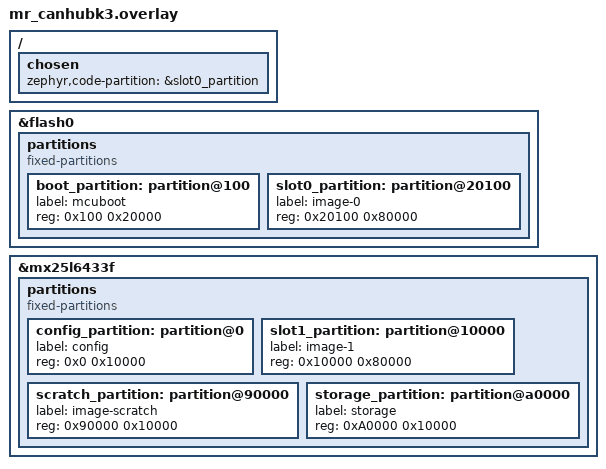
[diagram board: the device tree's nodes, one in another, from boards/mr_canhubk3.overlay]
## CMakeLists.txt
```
cmake_minimum_required(VERSION 3.20.0)

find_package(Zephyr REQUIRED HINTS $ENV{ZEPHYR_BASE})
project(ceell VERSION 0.1.0)

add_subdirectory(ceell)

target_sources(app PRIVATE src/main.c)
```

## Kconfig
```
mainmenu "CEELL Middleware Configuration"

rsource "Kconfig.ceell"

source "Kconfig.zephyr"
```

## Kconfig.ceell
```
menu "CEELL Services"

config CEELL_MAX_SERVICES
	int "Maximum number of services per node"
	default 4

config CEELL_MSG_PORT
	int "UDP port for service messaging"
	default 5556

config CEELL_PEER_TIMEOUT_MS
	int "Peer expiry timeout in milliseconds"
	default 5000

config CEELL_TEST_ECHO_SERVICE
	bool "Enable built-in echo test service"
	default n

endmenu

menu "CEELL Discovery"

config CEELL_DISCOVERY_PORT
	int "UDP port for discovery"
	default 5555

config CEELL_DISCOVERY_GROUP
	string "Multicast group address"
	default "224.0.1.100"

config CEELL_DISCOVERY_INTERVAL_MS
	int "Announcement interval in milliseconds"
	default 1000

config CEELL_DISCOVERY_MAX_PEERS
	int "Maximum number of tracked peers"
	default 8

endmenu

menu "CEELL Node Identity"

config CEELL_NODE_ID_DEFAULT
	int "Default node ID (used if flash config is empty)"
	default 0

config CEELL_NODE_ROLE_DEFAULT
	string "Default node role"
	default "unknown"

config CEELL_NODE_NAME_DEFAULT
	string "Default node name"
	default "ceell-unprovisioned"

config CEELL_NODE_IP_DEFAULT
	string "Default IP address"
	default "192.168.1.100"

config CEELL_NODE_NETMASK_DEFAULT
	string "Default netmask"
	default "255.255.255.0"

endmenu

menu "CEELL OTA Firmware Updates"

config CEELL_OTA
	bool "Enable OTA firmware update client"
	default n
	depends on BOOTLOADER_MCUBOOT
	depends on NET_TCP
	depends on HTTP_CLIENT
	depends on IMG_MANAGER
	depends on STREAM_FLASH
	help
	  Enable over-the-air firmware update support. The OTA client
	  periodically polls an HTTP server for a firmware manifest,
	  downloads new images to the secondary slot, and triggers
	  MCUboot to swap on reboot.

config CEELL_OTA_SERVER_HOST
	string "OTA server IP address"
	default "192.168.1.1"
	depends on CEELL_OTA

config CEELL_OTA_SERVER_PORT
	int "OTA server HTTP port"
	default 8080
	depends on CEELL_OTA

config CEELL_OTA_CHECK_INTERVAL_SEC
	int "Seconds between automatic update checks"
	default 300
	depends on CEELL_OTA

config CEELL_OTA_MANIFEST_PATH
	string "HTTP path to firmware manifest JSON"
	default "/firmware/latest.json"
	depends on CEELL_OTA

config CEELL_OTA_AUTO_CONFIRM
	bool "Automatically confirm image on successful boot"
	default y
	depends on CEELL_OTA
	help
	  When enabled, the running firmware is automatically confirmed
	  after a successful boot. If disabled, the application must
	  call boot_write_img_confirmed() explicitly — otherwise MCUboot
	  will revert to the previous image on the next reboot.

config CEELL_OTA_USE_TLS
	bool "Use HTTPS for OTA downloads"
	default n
	depends on CEELL_OTA
	depends on TLS_CREDENTIALS
	help
	  Enable TLS for OTA downloads. Requires additional heap (~49KB)
	  and a TLS credential configured for the server certificate.

endmenu

menu "CEELL Safety Messaging"

config CEELL_MSG_DISPATCHER_PRIORITY
	int "Dispatcher thread priority"
	default 5
	help
	  Priority of the message dispatcher thread. This thread reads
	  incoming UDP packets and routes them to per-priority queues.
	  Should be higher priority (lower number) than normal handlers.

config CEELL_MSG_CRITICAL_PRIORITY
	int "Critical message handler thread priority"
	default 2
	help
	  Priority of the thread that processes CRITICAL (safety) messages.
	  This is the highest priority handler — used for brake, steer, and
	  other safety-critical commands. Must be lower (higher priority)
	  than all other handler threads.

config CEELL_MSG_NORMAL_PRIORITY
	int "Normal message handler thread priority"
	default 7
	help
	  Priority of the thread that processes NORMAL (standard) messages.
	  Used for regular service requests and responses.

config CEELL_MSG_BULK_PRIORITY
	int "Bulk message handler thread priority"
	default 10
	help
	  Priority of the thread that processes BULK (low priority) messages.
	  Used for diagnostics, OTA status, and telemetry. Runs at the
	  lowest priority of all handler threads.

config CEELL_MSG_QUEUE_DEPTH
	int "Per-priority message queue depth"
	default 8
	help
	  Maximum number of messages that can be queued for each priority
	  level (CRITICAL, NORMAL, BULK). If a queue is full, incoming
	  messages of that priority are dropped with an error response.

endmenu

menu "CEELL Timing & Determinism"

config CEELL_TIMING
	bool "Enable timing measurement framework"
	default y
	help
	  Enable the timing measurement subsystem. Provides a ring buffer
	  of timing samples with per-label statistics (min/max/avg).
	  Uses the hardware cycle counter for sub-microsecond precision.

config CEELL_TIMING_SAMPLES
	int "Number of timing sample slots in ring buffer"
	default 64
	depends on CEELL_TIMING
	help
	  Size of the ring buffer that stores timing measurements.
	  Older samples are overwritten when the buffer is full.

config CEELL_TIMING_BUDGETS
	bool "Enable timing budget checks"
	default y
	depends on CEELL_TIMING
	help
	  Enable timing budgets for critical code paths. Each budget
	  defines a maximum acceptable duration; violations are counted
	  and repeated consecutive violations (3+) trigger a warning
	  that would escalate to safe state in production.

config CEELL_TSN
	bool "Enable TSN traffic class mapping"
	default n
	help
	  Enable IEEE 802.1Q TSN (Time-Sensitive Networking) traffic class
	  mapping. Maps CEELL message priorities to 802.1Q PCP values.
	  Currently stubbed — requires TSN-capable hardware (e.g. S32K5xx
	  ENETC) for actual queue scheduling.

endmenu

menu "CEELL Redundancy & Fault Tolerance"

config CEELL_MSG_REDUNDANT
	bool "Enable dual-path redundant messaging"
	default n
	help
	  Enable a secondary UDP socket for redundant message delivery.
	  Messages are sent on both the primary and secondary paths.
	  A deduplication ring buffer discards duplicate sequence numbers
	  received on either path.

config CEELL_MSG_PORT_SECONDARY
	int "Secondary UDP port for redundant messaging"
	default 5557
	depends on CEELL_MSG_REDUNDANT
	help
	  UDP port number for the secondary redundant messaging path.

config CEELL_SAFE_STATE
	bool "Enable safe state management"
	default y
	help
	  Enable the safe state manager. Provides an atomic safe-state
	  flag with callback notification. Modules can trigger safe state
	  when critical faults are detected (peer loss, deadline exceeded,
	  communication failure).

config CEELL_WATCHDOG
	bool "Enable software watchdog"
	default n
	depends on CEELL_SAFE_STATE
	help
	  Enable a software watchdog timer. If ceell_watchdog_feed() is not
	  called within the configured timeout, the watchdog triggers safe
	  state via ceell_safe_state_trigger(). The lifecycle loop should
	  call ceell_watchdog_feed() each tick.

config CEELL_WATCHDOG_TIMEOUT_MS
	int "Software watchdog timeout in milliseconds"
	default 10000
	depends on CEELL_WATCHDOG
	help
	  Maximum time between watchdog feeds before safe state is triggered.
	  Should be set to a value larger than the lifecycle tick interval.

endmenu
```

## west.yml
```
manifest:
  remotes:
    - name: zephyrproject-rtos
      url-base: https://github.com/zephyrproject-rtos

  projects:
    - name: zephyr
      remote: zephyrproject-rtos
      revision: v4.1.0
      import:
        name-allowlist:
          - cmsis
          - hal_nxp
          - picolibc
          - mbedtls
          - zcbor
    - name: mcuboot
      remote: zephyrproject-rtos
      revision: 346f7374ff4467e40b5594658f8ac67a5e9813c9
      path: bootloader/mcuboot

  self:
    path: ceell-app
```

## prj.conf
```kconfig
# CEELL Middleware - Base Configuration

# Networking
CONFIG_NETWORKING=y
CONFIG_NET_IPV4=y
CONFIG_NET_UDP=y
CONFIG_NET_SOCKETS=y
CONFIG_NET_IPV4_IGMP=y
CONFIG_NET_L2_ETHERNET=y
CONFIG_NET_DHCPV4=n

# IP set programmatically by ceell_net_setup() — no compile-time address
CONFIG_NET_CONFIG_SETTINGS=n

# Network buffers
CONFIG_NET_PKT_RX_COUNT=16
CONFIG_NET_PKT_TX_COUNT=16
CONFIG_NET_BUF_RX_COUNT=32
CONFIG_NET_BUF_TX_COUNT=32
CONFIG_NET_MAX_CONTEXTS=6

# JSON
CONFIG_JSON_LIBRARY=y

# Flash
CONFIG_FLASH=y
CONFIG_FLASH_MAP=y

# Threading
CONFIG_MAIN_STACK_SIZE=2048
CONFIG_SYSTEM_WORKQUEUE_STACK_SIZE=2048

# Logging
CONFIG_PRINTK=y

# Random (needed by networking stack)
CONFIG_TEST_RANDOM_GENERATOR=y

# No dynamic allocation
CONFIG_HEAP_MEM_POOL_SIZE=0

# CEELL app defaults (un-provisioned identity)
CONFIG_CEELL_DISCOVERY_PORT=5555
CONFIG_CEELL_DISCOVERY_GROUP="224.0.1.100"
CONFIG_CEELL_DISCOVERY_INTERVAL_MS=1000
CONFIG_CEELL_DISCOVERY_MAX_PEERS=8
CONFIG_CEELL_NODE_ID_DEFAULT=0
CONFIG_CEELL_NODE_ROLE_DEFAULT="unknown"
CONFIG_CEELL_NODE_NAME_DEFAULT="ceell-unprovisioned"
CONFIG_CEELL_NODE_IP_DEFAULT="192.168.1.100"
CONFIG_CEELL_NODE_NETMASK_DEFAULT="255.255.255.0"
CONFIG_CEELL_MAX_SERVICES=4
CONFIG_CEELL_MSG_PORT=5556
CONFIG_CEELL_PEER_TIMEOUT_MS=5000
CONFIG_CEELL_TEST_ECHO_SERVICE=y
```

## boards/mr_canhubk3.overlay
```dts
/* CEELL device tree overlay for MR-CANHUBK3
 * Flash layout for MCUboot + OTA firmware updates
 *
 * Internal flash (flash0, ~4MB @ 0x400000):
 *   0x000    -  0x0FF     ivt_header      (256B, from base DTS)
 *   0x100    -  0x200FF   boot_partition  (128KB, MCUboot)
 *   0x20100  -  0xA00FF   slot0_partition (512KB, primary app)
 *
 * External QSPI (mx25l6433f, 8MB):
 *   0x00000  - 0x0FFFF    config_partition  (64KB, node JSON config)
 *   0x10000  - 0x8FFFF    slot1_partition   (512KB, OTA download target)
 *   0x90000  - 0x9FFFF    scratch_partition (64KB, MCUboot swap scratch)
 *   0xA0000  - 0xAFFFF    storage_partition (64KB, general storage)
 */

/* --- Internal flash: add MCUboot + slot0, replace code_partition --- */
&flash0 {
	partitions {
		compatible = "fixed-partitions";
		#address-cells = <1>;
		#size-cells = <1>;

		/* Delete the default code_partition from base DTS */
		/delete-node/ partition@100;

		boot_partition: partition@100 {
			label = "mcuboot";
			reg = <0x100 0x20000>;
		};

		slot0_partition: partition@20100 {
			label = "image-0";
			reg = <0x20100 0x80000>;
		};
	};
};

/* --- External QSPI: config + slot1 + scratch + storage --- */
&mx25l6433f {
	partitions {
		compatible = "fixed-partitions";
		#address-cells = <1>;
		#size-cells = <1>;

		/delete-node/ partition@0;

		config_partition: partition@0 {
			label = "config";
			reg = <0x0 0x10000>;
		};

		slot1_partition: partition@10000 {
			label = "image-1";
			reg = <0x10000 0x80000>;
		};

		scratch_partition: partition@90000 {
			label = "image-scratch";
			reg = <0x90000 0x10000>;
		};

		storage_partition: partition@a0000 {
			label = "storage";
			reg = <0xA0000 0x10000>;
		};
	};
};

/* Point code-partition to slot0 for MCUboot chain boot */
/ {
	chosen {
		zephyr,code-partition = &slot0_partition;
	};
};
```

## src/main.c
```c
/* REQ-SAF-001 */

#include <string.h>

#include "osal_log.h"
#include "config_parser.h"
#include "net_setup.h"
#include "node_identity.h"
#include "service_registry.h"
#include "discovery.h"
#include "messaging.h"
#include "lifecycle.h"
#include "health_monitor.h"
#include "safe_state.h"
#include "timing.h"

#ifdef CONFIG_CEELL_OTA
#include "ota_client.h"
#endif

#ifdef CONFIG_CEELL_TEST_ECHO_SERVICE
static int echo_handler(const char *payload, char *rsp_payload, size_t rsp_len)
{
	strncpy(rsp_payload, payload, rsp_len - 1);
	rsp_payload[rsp_len - 1] = '\0';
	return 0;
}
#endif

static void on_health_change(uint32_t node_id, int old_state, int new_state)
{
	ceell_printk("CEELL: Peer %u health: %d -> %d\n",
		     node_id, old_state, new_state);

	if (new_state == CEELL_HEALTH_LOST) {
		ceell_safe_state_trigger(CEELL_SAFE_CRITICAL_PEER_LOST);
		ceell_printk("CEELL: SAFE STATE TRIGGERED peer=%u\n", node_id);
	} else if (old_state == CEELL_HEALTH_LOST &&
		   new_state == CEELL_HEALTH_HEALTHY) {
		ceell_safe_state_clear();
		ceell_printk("CEELL: SAFE STATE CLEARED peer=%u\n", node_id);
	}
}

int main(void)
{
	struct ceell_config cfg;
	int ret;

	ceell_printk("CEELL middleware starting\n");

	/* Step 1: Load config from flash (or defaults) */
	ret = ceell_config_load(&cfg);
	if (ret < 0) {
		ceell_printk("CEELL: fatal config error (%d)\n", ret);
		return ret;
	}
	ceell_printk("CEELL: Config loaded (from_flash=%d version=%u)\n",
		     cfg.from_flash, cfg.version);

	/* Step 2: Set IP + netmask on Ethernet interface */
	ret = ceell_net_setup(&cfg);
	if (ret < 0) {
		ceell_printk("CEELL: net setup failed (%d)\n", ret);
		return ret;
	}

	/* Step 3: Set node identity */
	ret = ceell_identity_init(&cfg);
	if (ret < 0 && ret != -EALREADY) {
		ceell_printk("CEELL: identity init failed (%d)\n", ret);
		return ret;
	}

	/* Step 4: Initialize service registry */
	ceell_service_init();

	/* Step 5: Register services from config with SLA data */
	for (int i = 0; i < cfg.service_count; i++) {
		if (cfg.version == CEELL_CONFIG_VERSION_V2) {
			/* V2: register with per-service SLA */
			ret = ceell_service_register_sla(
				cfg.services[i], NULL,
				cfg.service_slas[i].priority,
				cfg.service_slas[i].deadline_ms);
		} else {
			/* V1 or defaults: register with default SLA */
			ret = ceell_service_register(cfg.services[i], NULL);
		}
		if (ret < 0) {
			ceell_printk("CEELL: failed to register service "
				     "'%s' (%d)\n", cfg.services[i], ret);
		}
	}

#ifdef CONFIG_CEELL_TEST_ECHO_SERVICE
	ceell_service_register("echo", echo_handler);
#endif

	/* Step 5b: Initialize timing subsystem */
	ceell_timing_init();
	ceell_printk("CEELL: Timing subsystem initialized\n");

	/* Step 5c: Initialize health monitor */
	ret = ceell_health_init();
	if (ret < 0) {
		ceell_printk("CEELL: health init failed (%d)\n", ret);
	} else {
		ceell_health_register_cb(on_health_change);
		ceell_printk("CEELL: Health monitor initialized\n");
	}

	/* Step 5d: Initialize safe state manager */
	ret = ceell_safe_state_init();
	if (ret < 0) {
		ceell_printk("CEELL: safe state init failed (%d)\n", ret);
	} else {
		ceell_printk("CEELL: Safe state manager initialized\n");
	}

	/* Step 6: Initialize discovery */
	ret = ceell_discovery_init();
	if (ret < 0) {
		ceell_printk("CEELL: discovery init failed (%d)\n", ret);
		return ret;
	}

	/* Step 7: Start discovery threads */
	ceell_discovery_start();
	ceell_printk("CEELL: Discovery started\n");

	/* Step 8: Initialize messaging */
	ret = ceell_messaging_init();
	if (ret < 0) {
		ceell_printk("CEELL: messaging init failed (%d)\n", ret);
		return ret;
	}

#ifdef CONFIG_CEELL_OTA
	/* Step 9: Register OTA service + start OTA thread */
	ceell_service_register("ota", ceell_ota_service_handler);

	ret = ceell_ota_init();
	if (ret < 0) {
		ceell_printk("CEELL: OTA init failed (%d)\n", ret);
		/* Non-fatal: node runs without OTA */
	} else {
		ceell_printk("CEELL: OTA initialized\n");
	}
#endif

	/* Step 10: Lifecycle loop (never returns) */
	ceell_lifecycle_run();

	return 0;
}
```
